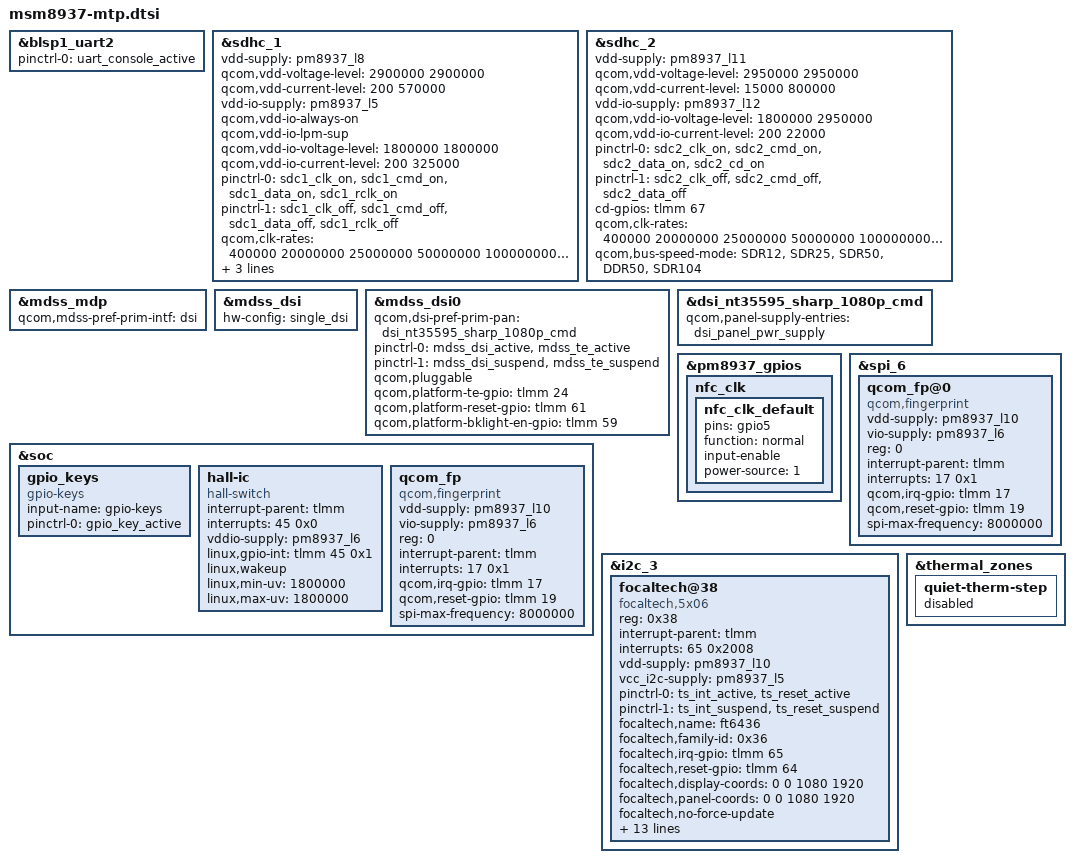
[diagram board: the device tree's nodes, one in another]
/*
 * Copyright (c) 2015-2016, 2018, The Linux Foundation. All rights reserved.
 *
 * This program is free software; you can redistribute it and/or modify
 * it under the terms of the GNU General Public License version 2 and
 * only version 2 as published by the Free Software Foundation.
 *
 * This program is distributed in the hope that it will be useful,
 * but WITHOUT ANY WARRANTY; without even the implied warranty of
 * MERCHANTABILITY or FITNESS FOR A PARTICULAR PURPOSE.  See the
 * GNU General Public License for more details.
 */

#include "msm8937-camera-sensor-mtp.dtsi"

#include "msm8937-pinctrl.dtsi"
&blsp1_uart2 {
	status = "ok";
	pinctrl-names = "default";
	pinctrl-0 = <&uart_console_active>;
};

&sdhc_1 {
	/* device core power supply */
	vdd-supply = <&pm8937_l8>;
	qcom,vdd-voltage-level = <2900000 2900000>;
	qcom,vdd-current-level = <200 570000>;

	/* device communication power supply */
	vdd-io-supply = <&pm8937_l5>;
	qcom,vdd-io-always-on;
	qcom,vdd-io-lpm-sup;
	qcom,vdd-io-voltage-level = <1800000 1800000>;
	qcom,vdd-io-current-level = <200 325000>;

	pinctrl-names = "active", "sleep";
	pinctrl-0 = <&sdc1_clk_on &sdc1_cmd_on &sdc1_data_on &sdc1_rclk_on>;
	pinctrl-1 = <&sdc1_clk_off &sdc1_cmd_off &sdc1_data_off &sdc1_rclk_off>;

	qcom,clk-rates = <400000 20000000 25000000 50000000 100000000 192000000
								384000000>;
	qcom,nonremovable;
	qcom,bus-speed-mode = "HS400_1p8v", "HS200_1p8v", "DDR_1p8v";

	status = "ok";
};

&sdhc_2 {
	/* device core power supply */
	vdd-supply = <&pm8937_l11>;
	qcom,vdd-voltage-level = <2950000 2950000>;
	qcom,vdd-current-level = <15000 800000>;

	/* device communication power supply */
	vdd-io-supply = <&pm8937_l12>;
	qcom,vdd-io-voltage-level = <1800000 2950000>;
	qcom,vdd-io-current-level = <200 22000>;

	pinctrl-names = "active", "sleep";
	pinctrl-0 = <&sdc2_clk_on &sdc2_cmd_on &sdc2_data_on &sdc2_cd_on>;
	pinctrl-1 = <&sdc2_clk_off &sdc2_cmd_off &sdc2_data_off>;

	cd-gpios = <&tlmm 67 0x0>;

	qcom,clk-rates = <400000 20000000 25000000 50000000 100000000
								200000000>;
	qcom,bus-speed-mode = "SDR12", "SDR25", "SDR50", "DDR50", "SDR104";

	status = "ok";
};

#include "msm8937-mdss-panels.dtsi"

&mdss_mdp {
	qcom,mdss-pref-prim-intf = "dsi";
};

&mdss_dsi {
	hw-config = "single_dsi";
};

&mdss_dsi0 {
	qcom,dsi-pref-prim-pan = <&dsi_nt35595_sharp_1080p_cmd>;
	pinctrl-names = "mdss_default", "mdss_sleep";
	pinctrl-0 = <&mdss_dsi_active &mdss_te_active>;
	pinctrl-1 = <&mdss_dsi_suspend &mdss_te_suspend>;

	qcom,pluggable;
	qcom,platform-te-gpio = <&tlmm 24 0>;
	qcom,platform-reset-gpio = <&tlmm 61 0>;
	qcom,platform-bklight-en-gpio = <&tlmm 59 0>;
};

&dsi_nt35595_sharp_1080p_cmd {
	qcom,panel-supply-entries = <&dsi_panel_pwr_supply>;
};

&soc {
	gpio_keys {
		compatible = "gpio-keys";
		input-name = "gpio-keys";
		pinctrl-names = "default";
		pinctrl-0 = <&gpio_key_active>;
	}

	hall-ic {
		compatible = "hall-switch";
		interrupt-parent = <&tlmm>;
		interrupts = <45 0x0>;
		vddio-supply = <&pm8937_l6>;
		linux,gpio-int = <&tlmm 45 0x1>;
		linux,wakeup;
		linux,min-uv = <1800000>;
		linux,max-uv = <1800000>;
	};

	qcom_fp {
		status = "ok";
		compatible = "qcom,fingerprint";
		vdd-supply = <&pm8937_l10>;
		vio-supply = <&pm8937_l6>;
		reg = <0>;
		interrupt-parent = <&tlmm>;
		interrupts = <17 0x1>;
		qcom,irq-gpio = <&tlmm 17 0x00>;
		qcom,reset-gpio = <&tlmm 19 0x00>;
		spi-max-frequency = <8000000>;
	};
};

&pm8937_gpios {
	nfc_clk {
		nfc_clk_default: nfc_clk_default {
			pins = "gpio5";
			function = "normal";
			input-enable;
			power-source = <1>;
		};
	};
};

&spi_6 {
    	qcom_fp@0 {
        	status = "ok";
        	compatible = "qcom,fingerprint";
        	vdd-supply = <&pm8937_l10>;
        	vio-supply = <&pm8937_l6>;
        	reg = <0>;
        	interrupt-parent = <&tlmm>;
        	interrupts = <17 0x1>;
        	qcom,irq-gpio = <&tlmm 17 0x00>;
        	qcom,reset-gpio = <&tlmm 19 0x00>;
        	spi-max-frequency = <8000000>;
   	};
};

&i2c_3 {
	focaltech@38 {
		compatible = "focaltech,5x06";
		reg = <0x38>;
		interrupt-parent = <&tlmm>;
		interrupts = <65 0x2008>;
		vdd-supply = <&pm8937_l10>;
		vcc_i2c-supply = <&pm8937_l5>;
		/* pins used by touchscreen */
		pinctrl-names = "pmx_ts_active","pmx_ts_suspend";
		pinctrl-0 = <&ts_int_active &ts_reset_active>;
		pinctrl-1 = <&ts_int_suspend &ts_reset_suspend>;
		focaltech,name = "ft6436";
		focaltech,family-id = <0x36>;
		focaltech,irq-gpio = <&tlmm 65 0x0>;
		focaltech,reset-gpio = <&tlmm 64 0x0>;
		focaltech,display-coords = <0 0 1080 1920>;
		focaltech,panel-coords = <0 0 1080 1920>;
		focaltech,no-force-update;
		focaltech,i2c-pull-up;
		focaltech,group-id = <1>;
		focaltech,hard-reset-delay-ms = <20>;
		focaltech,soft-reset-delay-ms = <200>;
		focaltech,num-max-touches = <5>;
		focaltech,fw-delay-aa-ms = <30>;
		focaltech,fw-delay-55-ms = <30>;
		focaltech,fw-upgrade-id1 = <0x79>;
		focaltech,fw-upgrade-id2 = <0x18>;
		focaltech,fw-delay-readid-ms = <10>;
		focaltech,fw-delay-era-flsh-ms = <2000>;
		focaltech,fw-auto-cal;
		focaltech,ignore-id-check;
	};
};

&thermal_zones {
	quiet-therm-step {
		status = "disabled";
	};
};
